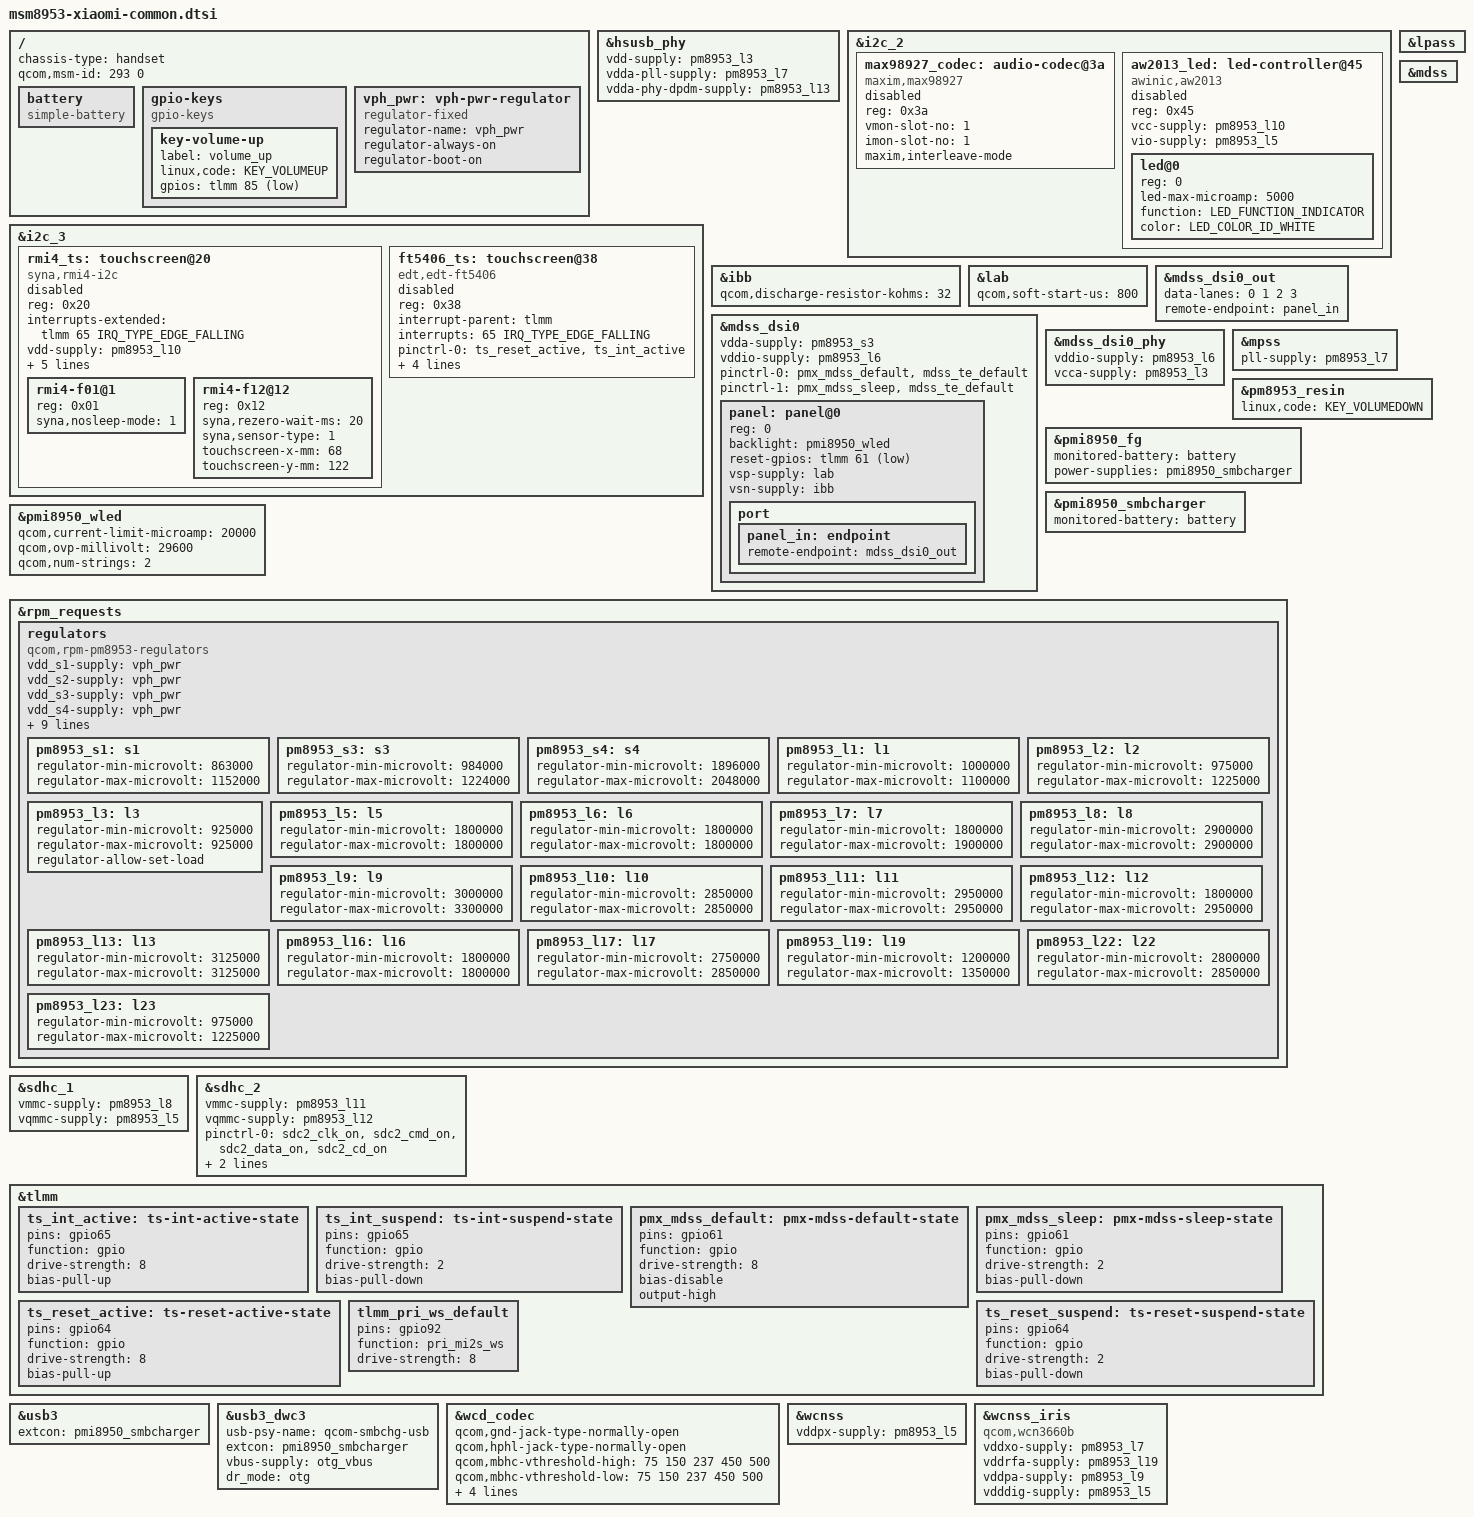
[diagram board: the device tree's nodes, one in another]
// SPDX-License-Identifier: BSD-3-Clause
/dts-v1/;

#include "msm8953.dtsi"
#include "pm8953.dtsi"
#include "pmi8950.dtsi"
#include <dt-bindings/leds/common.h>

/ {
	chassis-type = "handset";
	qcom,msm-id = <293 0>;

	battery: battery {
		compatible = "simple-battery";
	};

	gpio-keys {
		compatible = "gpio-keys";

		key-volume-up {
			label = "volume_up";
			linux,code = <KEY_VOLUMEUP>;
			gpios = <&tlmm 85 GPIO_ACTIVE_LOW>;
		};
	};

	vph_pwr: vph-pwr-regulator {
		compatible = "regulator-fixed";
		regulator-name = "vph_pwr";
		regulator-always-on;
		regulator-boot-on;
	};
};

&hsusb_phy {
	vdd-supply = <&pm8953_l3>;
	vdda-pll-supply = <&pm8953_l7>;
	vdda-phy-dpdm-supply = <&pm8953_l13>;

	status = "okay";
};

&i2c_2 {
	status = "okay";

	max98927_codec: audio-codec@3a {
		compatible = "maxim,max98927";
		reg = <0x3a>;
		status = "disabled";

		vmon-slot-no = <1>;
		imon-slot-no = <1>;
		maxim,interleave-mode;

		#sound-dai-cells = <0>;
	};

	aw2013_led: led-controller@45 {
		compatible = "awinic,aw2013";
		reg = <0x45>;

		vcc-supply = <&pm8953_l10>;
		vio-supply = <&pm8953_l5>;

		status = "disabled";

		#address-cells = <1>;
		#size-cells = <0>;

		led@0 {
			reg = <0>;
			led-max-microamp = <5000>;
			function = LED_FUNCTION_INDICATOR;
			color = <LED_COLOR_ID_WHITE>;
		};
	};
};

&i2c_3 {
	status = "okay";

	rmi4_ts: touchscreen@20 {
		reg = <0x20>;
		compatible = "syna,rmi4-i2c";
		interrupts-extended = <&tlmm 65 IRQ_TYPE_EDGE_FALLING>;

		#address-cells = <1>;
		#size-cells = <0>;

		vdd-supply = <&pm8953_l10>;
		vio-supply = <&pm8953_l6>;

		pinctrl-names = "default", "sleep";
		pinctrl-0 = <&ts_reset_active &ts_int_active>;
		pinctrl-1 = <&ts_reset_suspend &ts_int_suspend>;

		syna,reset-delay-ms = <200>;
		syna,startup-delay-ms = <500>;

		status = "disabled";

		rmi4-f01@1 {
			reg = <0x01>;
			syna,nosleep-mode = <1>;
		};

		rmi4-f12@12 {
			reg = <0x12>;
			syna,rezero-wait-ms = <20>;
			syna,sensor-type = <1>;
			touchscreen-x-mm = <68>;
			touchscreen-y-mm = <122>;
		};
	};

	ft5406_ts: touchscreen@38 {
		compatible = "edt,edt-ft5406";
		reg = <0x38>;

		interrupt-parent = <&tlmm>;
		interrupts = <65 IRQ_TYPE_EDGE_FALLING>;

		pinctrl-names = "default", "sleep";
		pinctrl-0 = <&ts_reset_active &ts_int_active>;
		pinctrl-1 = <&ts_reset_suspend &ts_int_suspend>;

		reset-gpios = <&tlmm 64 GPIO_ACTIVE_LOW>;

		iovcc-supply = <&pm8953_l6>;
		vcc-supply = <&pm8953_l10>;

		status = "disabled";
	};
};

&ibb {
	qcom,discharge-resistor-kohms = <32>;
};

&lab {
	qcom,soft-start-us = <800>;
};

&lpass {
	status = "okay";
};

&mdss {
	status = "okay";
};

&mdss_dsi0 {
	vdda-supply = <&pm8953_s3>;
	vddio-supply = <&pm8953_l6>;

	pinctrl-0 = <&pmx_mdss_default &mdss_te_default>;
	pinctrl-1 = <&pmx_mdss_sleep &mdss_te_default>;
	pinctrl-names = "default", "sleep";

	status = "okay";

	panel: panel@0 {
		reg = <0>;

		backlight = <&pmi8950_wled>;

		reset-gpios = <&tlmm 61 GPIO_ACTIVE_LOW>;

		vsp-supply = <&lab>;
		vsn-supply = <&ibb>;

		port {
			panel_in: endpoint {
				remote-endpoint = <&mdss_dsi0_out>;
			};
		};
	};
};

&mdss_dsi0_out {
	data-lanes = <0 1 2 3>;
	remote-endpoint = <&panel_in>;
};

&mdss_dsi0_phy {
	vddio-supply = <&pm8953_l6>;
	vcca-supply = <&pm8953_l3>;

	status = "okay";
};

&mpss {
	pll-supply = <&pm8953_l7>;

	status = "okay";
};

&pm8953_resin {
	linux,code = <KEY_VOLUMEDOWN>;
	status = "okay";
};

&pmi8950_fg {
	monitored-battery = <&battery>;
	power-supplies = <&pmi8950_smbcharger>;
	status = "okay";
};

&pmi8950_smbcharger {
	monitored-battery = <&battery>;
	status = "okay";
};

&pmi8950_wled {
	qcom,current-limit-microamp = <20000>;
	qcom,ovp-millivolt = <29600>;
	qcom,num-strings = <2>;

	status = "okay";
};

&rpm_requests {
	regulators {
		compatible = "qcom,rpm-pm8953-regulators";

		vdd_s1-supply = <&vph_pwr>;
		vdd_s2-supply = <&vph_pwr>;
		vdd_s3-supply = <&vph_pwr>;
		vdd_s4-supply = <&vph_pwr>;
		vdd_s5-supply = <&vph_pwr>;
		vdd_s6-supply = <&vph_pwr>;
		vdd_s7-supply = <&vph_pwr>;
		vdd_l1-supply = <&pm8953_s3>;
		vdd_l2_l3-supply = <&pm8953_s3>;
		vdd_l4_l5_l6_l7_l16_l19-supply = <&pm8953_s4>;
		vdd_l8_l11_l12_l13_l14_l15-supply = <&vph_pwr>;
		vdd_l9_l10_l17_l18_l22-supply = <&vph_pwr>;
		vdd_l23-supply = <&pm8953_s3>;

		pm8953_s1: s1 {
			regulator-min-microvolt = <863000>;
			regulator-max-microvolt = <1152000>;
		};

		pm8953_s3: s3 {
			regulator-min-microvolt = <984000>;
			regulator-max-microvolt = <1224000>;
		};

		pm8953_s4: s4 {
			regulator-min-microvolt = <1896000>;
			regulator-max-microvolt = <2048000>;
		};

		pm8953_l1: l1 {
			regulator-min-microvolt = <1000000>;
			regulator-max-microvolt = <1100000>;
		};

		pm8953_l2: l2 {
			regulator-min-microvolt = <975000>;
			regulator-max-microvolt = <1225000>;
		};

		pm8953_l3: l3 {
			regulator-min-microvolt = <925000>;
			regulator-max-microvolt = <925000>;
			regulator-allow-set-load;
		};

		pm8953_l5: l5 {
			regulator-min-microvolt = <1800000>;
			regulator-max-microvolt = <1800000>;
		};

		pm8953_l6: l6 {
			regulator-min-microvolt = <1800000>;
			regulator-max-microvolt = <1800000>;
		};

		pm8953_l7: l7 {
			regulator-min-microvolt = <1800000>;
			regulator-max-microvolt = <1900000>;
		};

		pm8953_l8: l8 {
			regulator-min-microvolt = <2900000>;
			regulator-max-microvolt = <2900000>;
		};

		pm8953_l9: l9 {
			regulator-min-microvolt = <3000000>;
			regulator-max-microvolt = <3300000>;
		};

		pm8953_l10: l10 {
			regulator-min-microvolt = <2850000>;
			regulator-max-microvolt = <2850000>;
		};

		pm8953_l11: l11 {
			regulator-min-microvolt = <2950000>;
			regulator-max-microvolt = <2950000>;
		};

		pm8953_l12: l12 {
			regulator-min-microvolt = <1800000>;
			regulator-max-microvolt = <2950000>;
		};

		pm8953_l13: l13 {
			regulator-min-microvolt = <3125000>;
			regulator-max-microvolt = <3125000>;
		};

		pm8953_l16: l16 {
			regulator-min-microvolt = <1800000>;
			regulator-max-microvolt = <1800000>;
		};

		pm8953_l17: l17 {
			regulator-min-microvolt = <2750000>;
			regulator-max-microvolt = <2850000>;
		};

		pm8953_l19: l19 {
			regulator-min-microvolt = <1200000>;
			regulator-max-microvolt = <1350000>;
		};

		pm8953_l22: l22 {
			regulator-min-microvolt = <2800000>;
			regulator-max-microvolt = <2850000>;
		};

		pm8953_l23: l23 {
			regulator-min-microvolt = <975000>;
			regulator-max-microvolt = <1225000>;
		};
	};
};

&sdhc_1 {
	vmmc-supply = <&pm8953_l8>;
	vqmmc-supply = <&pm8953_l5>;

	status = "okay";
};

&sdhc_2 {
	vmmc-supply = <&pm8953_l11>;
	vqmmc-supply = <&pm8953_l12>;

	pinctrl-names = "default", "sleep";
	pinctrl-0 = <&sdc2_clk_on &sdc2_cmd_on &sdc2_data_on &sdc2_cd_on>;
	pinctrl-1 = <&sdc2_clk_off &sdc2_cmd_off &sdc2_data_off &sdc2_cd_off>;

	status = "okay";
};

&tlmm {
	ts_int_active: ts-int-active-state {
		pins = "gpio65";
		function = "gpio";
		drive-strength = <8>;
		bias-pull-up;
	};

	ts_int_suspend: ts-int-suspend-state {
		pins = "gpio65";
		function = "gpio";
		drive-strength = <2>;
		bias-pull-down;
	};

	pmx_mdss_default: pmx-mdss-default-state {
		pins = "gpio61";
		function = "gpio";
		drive-strength = <8>;
		bias-disable;
		output-high;
	};

	pmx_mdss_sleep: pmx-mdss-sleep-state {
		pins = "gpio61";
		function = "gpio";
		drive-strength = <2>;
		bias-pull-down;
	};

	ts_reset_active: ts-reset-active-state {
		pins = "gpio64";
		function = "gpio";
		drive-strength = <8>;
		bias-pull-up;
	};

	ts_reset_suspend: ts-reset-suspend-state {
		pins = "gpio64";
		function = "gpio";
		drive-strength = <2>;
		bias-pull-down;
	};

	tlmm_pri_ws_default: tlmm_pri_ws_default {
		pins = "gpio92";
		function = "pri_mi2s_ws";
		drive-strength = <8>;
	};
};

&usb3 {
	extcon = <&pmi8950_smbcharger>;
	status = "okay";
};

&usb3_dwc3 {
	usb-psy-name = "qcom-smbchg-usb";
	extcon = <&pmi8950_smbcharger>;
	vbus-supply = <&otg_vbus>;
	dr_mode = "otg";
};

&wcd_codec {
	qcom,gnd-jack-type-normally-open;
	qcom,hphl-jack-type-normally-open;
	qcom,mbhc-vthreshold-high = <75 150 237 450 500>;
	qcom,mbhc-vthreshold-low = <75 150 237 450 500>;
	qcom,micbias1-ext-cap;

	vdd-cdc-io-supply = <&pm8953_l5>;
	vdd-cdc-tx-rx-cx-supply = <&pm8953_s4>;
	vdd-micbias-supply = <&pm8953_l13>;

	status = "okay";
};

&wcnss {
	vddpx-supply = <&pm8953_l5>;
	status = "okay";
};

&wcnss_iris {
	compatible = "qcom,wcn3660b";

	vddxo-supply = <&pm8953_l7>;
	vddrfa-supply = <&pm8953_l19>;
	vddpa-supply = <&pm8953_l9>;
	vdddig-supply = <&pm8953_l5>;

	status = "okay";
};
